AUTOSAR XML (schema 4-2-2)
package /STELLANTIS/EPT/COMSWCs
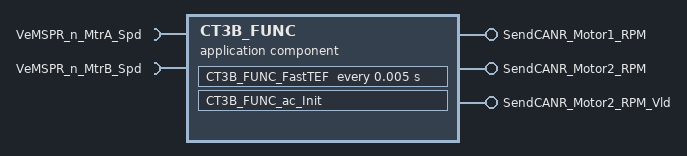
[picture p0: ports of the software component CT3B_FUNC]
  application sw component type CT3B_FUNC
    require port VeMSPR_n_MtrA_Spd: variation-point={short-label=vpVeMSPR_n_MtrA_Spd, sw-syscond=1}, nonqueued-receiver-com-spec{data-element=Value, init-value=0}, required-interface=VeMSPR_n_MtrA_Spd
    require port VeMSPR_n_MtrB_Spd: nonqueued-receiver-com-spec{data-element=Value, init-value=0}, required-interface=VeMSPR_n_MtrB_Spd
    provide port SendCANR_Motor1_RPM: variation-point={short-label=vpSendCANR_Motor1_RPM, sw-syscond=1}, nonqueued-sender-com-spec{data-element=SendCANR_Motor1_RPM, init-value=0}, provided-interface=SendCANR_Motor1_RPM
    provide port SendCANR_Motor2_RPM: nonqueued-sender-com-spec{data-element=SendCANR_Motor2_RPM, init-value=0}, provided-interface=SendCANR_Motor2_RPM
    provide port SendCANR_Motor2_RPM_Vld: nonqueued-sender-com-spec{data-element=SendCANR_Motor2_RPM_Vld, init-value=0}, provided-interface=SendCANR_Motor2_RPM_Vld
    behavior IB_CT3B_FUNC: data-type-mapping=[msADTtoIDTMapping, ADTtoIDTMapping], handle-termination-and-restart=NO-SUPPORT
      timing event Event_FastTEF: start-on-event=CT3B_FUNC_FastTEF, period=0.005
      init event Event_CT3B_FUNC_ac_Init: start-on-event=CT3B_FUNC_ac_Init
      runnable CT3B_FUNC_ac_Init
      runnable CT3B_FUNC_FastTEF
        data-receive-point-by-arguments:
          access IN_VeMSPR_n_MtrA_Spd_Value: accessed-variable=VeMSPR_n_MtrA_Spd.Value, variation-point={short-label=vpIN_VeMSPR_n_MtrA_Spd_Value, sw-syscond=1}
          access IN_VeMSPR_n_MtrB_Spd_Value: accessed-variable=VeMSPR_n_MtrB_Spd.Value
        data-send-points:
          access OUT_SendCANR_Motor1_RPM_SendCANR_Motor1_RPM: accessed-variable=SendCANR_Motor1_RPM.SendCANR_Motor1_RPM, variation-point={short-label=vpOUT_SendCANR_Motor1_RPM_SendCANR_Motor1_RPM, sw-syscond=1}
          access OUT_SendCANR_Motor2_RPM_SendCANR_Motor2_RPM: accessed-variable=SendCANR_Motor2_RPM.SendCANR_Motor2_RPM
          access OUT_SendCANR_Motor2_RPM_Vld_SendCANR_Motor2_RPM_Vld: accessed-variable=SendCANR_Motor2_RPM_Vld.SendCANR_Motor2_RPM_Vld
      variation point proxy VrntCT3B_Motor1RPM_MSPRnMtrASpd: category=CONDITION, condition-access=1
      variation point proxy VrntCT3B_Motor1RPM_MSPRnMtrCSpd: category=CONDITION, condition-access=0
